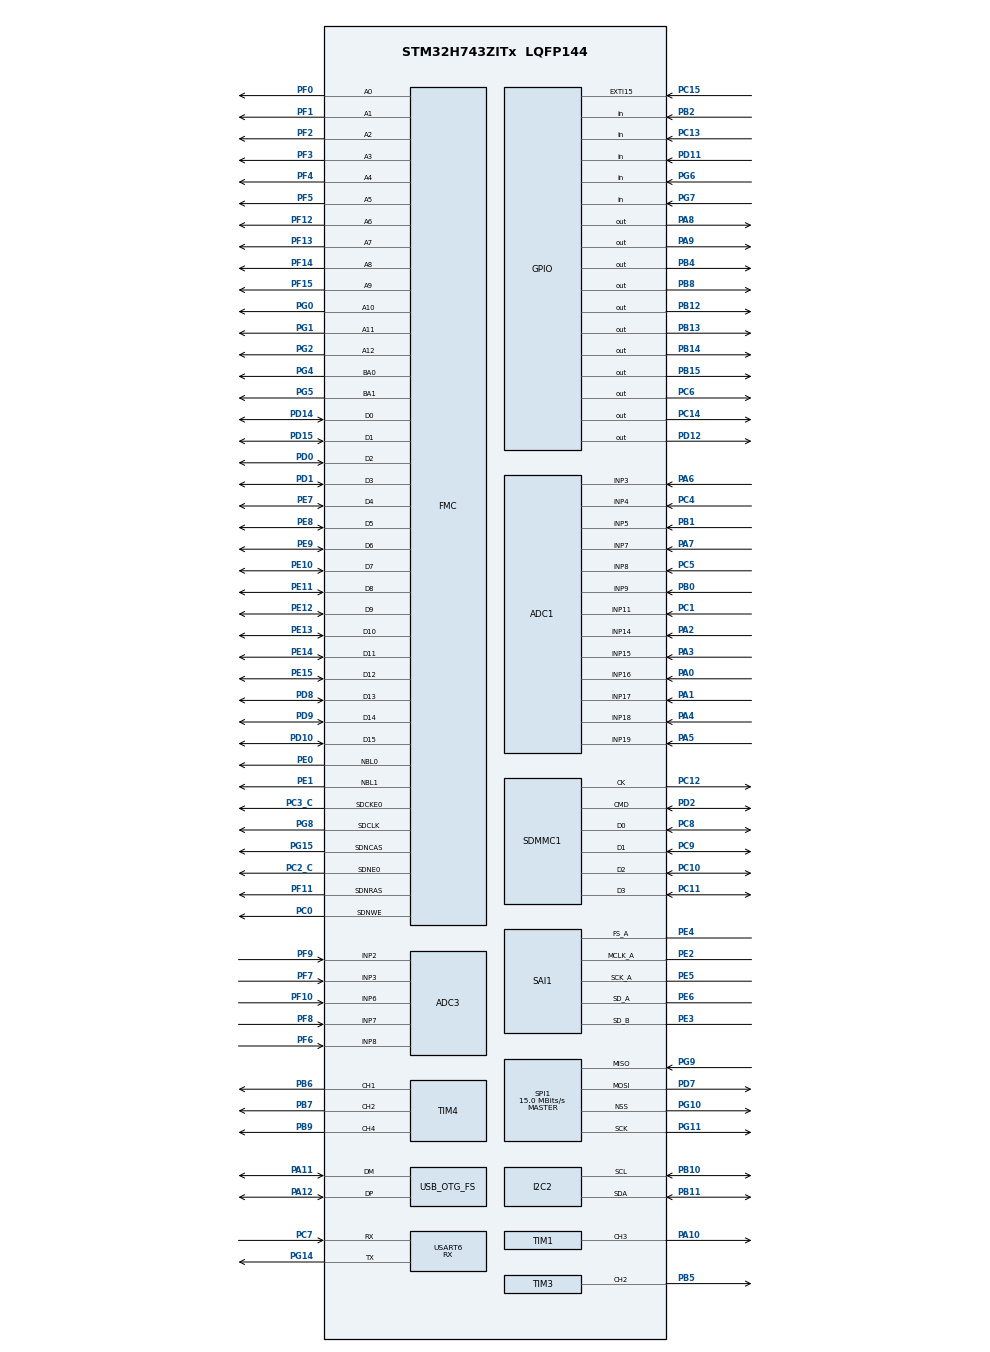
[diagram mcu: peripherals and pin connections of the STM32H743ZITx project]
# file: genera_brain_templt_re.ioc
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ADC1.Channel-0\#ChannelRegularConversion=ADC_CHANNEL_7
ADC1.Channel-1\#ChannelRegularConversion=ADC_CHANNEL_19
ADC1.Channel-2\#ChannelRegularConversion=ADC_CHANNEL_15
ADC1.Channel-3\#ChannelRegularConversion=ADC_CHANNEL_3
ADC1.Channel-4\#ChannelRegularConversion=ADC_CHANNEL_18
ADC1.Channel-5\#ChannelRegularConversion=ADC_CHANNEL_14
ADC1.Channel-6\#ChannelRegularConversion=ADC_CHANNEL_4
ADC1.Channel-7\#ChannelRegularConversion=ADC_CHANNEL_8
ADC1.Channel-8\#ChannelRegularConversion=ADC_CHANNEL_9
ADC1.Channel-9\#ChannelRegularConversion=ADC_CHANNEL_5
ADC1.ClockPrescaler=ADC_CLOCK_ASYNC_DIV16
ADC1.ContinuousConvMode=ENABLE
ADC1.ConversionDataManagement=ADC_CONVERSIONDATA_DMA_CIRCULAR
ADC1.EOCSelection=ADC_EOC_SEQ_CONV
ADC1.NbrOfConversion=10
ADC1.NbrOfConversionFlag=1
ADC1.OffsetNumber-0\#ChannelRegularConversion=ADC_OFFSET_NONE
ADC1.OffsetNumber-1\#ChannelRegularConversion=ADC_OFFSET_NONE
ADC1.OffsetNumber-2\#ChannelRegularConversion=ADC_OFFSET_NONE
ADC1.OffsetNumber-3\#ChannelRegularConversion=ADC_OFFSET_NONE
ADC1.OffsetNumber-4\#ChannelRegularConversion=ADC_OFFSET_NONE
ADC1.OffsetNumber-5\#ChannelRegularConversion=ADC_OFFSET_NONE
ADC1.OffsetNumber-6\#ChannelRegularConversion=ADC_OFFSET_NONE
ADC1.OffsetNumber-7\#ChannelRegularConversion=ADC_OFFSET_NONE
ADC1.OffsetNumber-8\#ChannelRegularConversion=ADC_OFFSET_NONE
ADC1.OffsetNumber-9\#ChannelRegularConversion=ADC_OFFSET_NONE
ADC1.OffsetSignedSaturation-6\#ChannelRegularConversion=DISABLE
ADC1.OffsetSignedSaturation-7\#ChannelRegularConversion=DISABLE
ADC1.OffsetSignedSaturation-8\#ChannelRegularConversion=DISABLE
ADC1.OffsetSignedSaturation-9\#ChannelRegularConversion=DISABLE
ADC1.Rank-0\#ChannelRegularConversion=1
ADC1.Rank-1\#ChannelRegularConversion=2
ADC1.Rank-2\#ChannelRegularConversion=3
ADC1.Rank-3\#ChannelRegularConversion=4
ADC1.Rank-4\#ChannelRegularConversion=5
ADC1.Rank-5\#ChannelRegularConversion=6
ADC1.Rank-6\#ChannelRegularConversion=7
ADC1.Rank-7\#ChannelRegularConversion=8
ADC1.Rank-8\#ChannelRegularConversion=9
ADC1.Rank-9\#ChannelRegularConversion=10
ADC1.SamplingTime-0\#ChannelRegularConversion=ADC_SAMPLETIME_387CYCLES_5
ADC1.SamplingTime-1\#ChannelRegularConversion=ADC_SAMPLETIME_387CYCLES_5
ADC1.SamplingTime-2\#ChannelRegularConversion=ADC_SAMPLETIME_387CYCLES_5
ADC1.SamplingTime-3\#ChannelRegularConversion=ADC_SAMPLETIME_387CYCLES_5
ADC1.SamplingTime-4\#ChannelRegularConversion=ADC_SAMPLETIME_387CYCLES_5
ADC1.SamplingTime-5\#ChannelRegularConversion=ADC_SAMPLETIME_387CYCLES_5
ADC1.SamplingTime-6\#ChannelRegularConversion=ADC_SAMPLETIME_1CYCLE_5
ADC1.SamplingTime-7\#ChannelRegularConversion=ADC_SAMPLETIME_1CYCLE_5
ADC1.SamplingTime-8\#ChannelRegularConversion=ADC_SAMPLETIME_1CYCLE_5
ADC1.SamplingTime-9\#ChannelRegularConversion=ADC_SAMPLETIME_1CYCLE_5
ADC1.master=1
ADC3.Channel-1\#ChannelRegularConversion=ADC_CHANNEL_2
ADC3.Channel-2\#ChannelRegularConversion=ADC_CHANNEL_2
ADC3.Channel-3\#ChannelRegularConversion=ADC_CHANNEL_2
ADC3.Channel-4\#ChannelRegularConversion=ADC_CHANNEL_2
ADC3.Channel-5\#ChannelRegularConversion=ADC_CHANNEL_2
ADC3.ClockPrescaler=ADC_CLOCK_ASYNC_DIV16
ADC3.ContinuousConvMode=ENABLE
ADC3.NbrOfConversion=5
ADC3.NbrOfConversionFlag=1
ADC3.OffsetNumber-1\#ChannelRegularConversion=ADC_OFFSET_NONE
ADC3.OffsetNumber-2\#ChannelRegularConversion=ADC_OFFSET_NONE
ADC3.OffsetNumber-3\#ChannelRegularConversion=ADC_OFFSET_NONE
ADC3.OffsetNumber-4\#ChannelRegularConversion=ADC_OFFSET_NONE
ADC3.OffsetNumber-5\#ChannelRegularConversion=ADC_OFFSET_NONE
ADC3.Rank-1\#ChannelRegularConversion=1
ADC3.Rank-2\#ChannelRegularConversion=2
ADC3.Rank-3\#ChannelRegularConversion=3
ADC3.Rank-4\#ChannelRegularConversion=4
ADC3.Rank-5\#ChannelRegularConversion=5
ADC3.SamplingTime-1\#ChannelRegularConversion=ADC_SAMPLETIME_1CYCLE_5
ADC3.SamplingTime-2\#ChannelRegularConversion=ADC_SAMPLETIME_1CYCLE_5
ADC3.SamplingTime-3\#ChannelRegularConversion=ADC_SAMPLETIME_1CYCLE_5
ADC3.SamplingTime-4\#ChannelRegularConversion=ADC_SAMPLETIME_1CYCLE_5
ADC3.SamplingTime-5\#ChannelRegularConversion=ADC_SAMPLETIME_1CYCLE_5
CORTEX_M7.CPU_DCache=Enabled
CORTEX_M7.CPU_ICache=Enabled
Dma.ADC1.0.Direction=DMA_PERIPH_TO_MEMORY
Dma.ADC1.0.EventEnable=DISABLE
Dma.ADC1.0.FIFOMode=DMA_FIFOMODE_ENABLE
Dma.ADC1.0.FIFOThreshold=DMA_FIFO_THRESHOLD_1QUARTERFULL
Dma.ADC1.0.Instance=DMA1_Stream0
Dma.ADC1.0.MemBurst=DMA_MBURST_SINGLE
Dma.ADC1.0.MemDataAlignment=DMA_MDATAALIGN_HALFWORD
Dma.ADC1.0.MemInc=DMA_MINC_ENABLE
Dma.ADC1.0.Mode=DMA_CIRCULAR
Dma.ADC1.0.PeriphBurst=DMA_PBURST_SINGLE
Dma.ADC1.0.PeriphDataAlignment=DMA_PDATAALIGN_HALFWORD
Dma.ADC1.0.PeriphInc=DMA_PINC_DISABLE
Dma.ADC1.0.Polarity=HAL_DMAMUX_REQ_GEN_RISING
Dma.ADC1.0.Priority=DMA_PRIORITY_HIGH
Dma.ADC1.0.RequestNumber=1
Dma.ADC1.0.SignalID=NONE
Dma.ADC1.0.SyncEnable=DISABLE
Dma.ADC1.0.SyncPolarity=HAL_DMAMUX_SYNC_NO_EVENT
Dma.ADC1.0.SyncRequestNumber=1
Dma.ADC1.0.SyncSignalID=NONE
Dma.Request0=ADC1
Dma.Request1=SAI1_A
Dma.Request2=SAI1_B
Dma.SAI1_A.1.Direction=DMA_MEMORY_TO_PERIPH
Dma.SAI1_A.1.EventEnable=DISABLE
Dma.SAI1_A.1.FIFOMode=DMA_FIFOMODE_ENABLE
Dma.SAI1_A.1.FIFOThreshold=DMA_FIFO_THRESHOLD_1QUARTERFULL
Dma.SAI1_A.1.Instance=DMA1_Stream1
Dma.SAI1_A.1.MemBurst=DMA_MBURST_SINGLE
Dma.SAI1_A.1.MemDataAlignment=DMA_MDATAALIGN_WORD
Dma.SAI1_A.1.MemInc=DMA_MINC_ENABLE
Dma.SAI1_A.1.Mode=DMA_CIRCULAR
Dma.SAI1_A.1.PeriphBurst=DMA_PBURST_SINGLE
Dma.SAI1_A.1.PeriphDataAlignment=DMA_PDATAALIGN_WORD
Dma.SAI1_A.1.PeriphInc=DMA_PINC_DISABLE
Dma.SAI1_A.1.Polarity=HAL_DMAMUX_REQ_GEN_RISING
Dma.SAI1_A.1.Priority=DMA_PRIORITY_VERY_HIGH
Dma.SAI1_A.1.RequestNumber=1
Dma.SAI1_A.1.SignalID=NONE
Dma.SAI1_A.1.SyncEnable=DISABLE
Dma.SAI1_A.1.SyncPolarity=HAL_DMAMUX_SYNC_NO_EVENT
Dma.SAI1_A.1.SyncRequestNumber=1
Dma.SAI1_A.1.SyncSignalID=NONE
Dma.SAI1_B.2.Direction=DMA_PERIPH_TO_MEMORY
Dma.SAI1_B.2.EventEnable=DISABLE
Dma.SAI1_B.2.FIFOMode=DMA_FIFOMODE_ENABLE
Dma.SAI1_B.2.FIFOThreshold=DMA_FIFO_THRESHOLD_1QUARTERFULL
Dma.SAI1_B.2.Instance=DMA1_Stream2
Dma.SAI1_B.2.MemBurst=DMA_MBURST_SINGLE
Dma.SAI1_B.2.MemDataAlignment=DMA_MDATAALIGN_WORD
Dma.SAI1_B.2.MemInc=DMA_MINC_ENABLE
Dma.SAI1_B.2.Mode=DMA_CIRCULAR
Dma.SAI1_B.2.PeriphBurst=DMA_PBURST_SINGLE
Dma.SAI1_B.2.PeriphDataAlignment=DMA_PDATAALIGN_WORD
Dma.SAI1_B.2.PeriphInc=DMA_PINC_DISABLE
Dma.SAI1_B.2.Polarity=HAL_DMAMUX_REQ_GEN_RISING
Dma.SAI1_B.2.Priority=DMA_PRIORITY_VERY_HIGH
Dma.SAI1_B.2.RequestNumber=1
Dma.SAI1_B.2.SignalID=NONE
Dma.SAI1_B.2.SyncEnable=DISABLE
Dma.SAI1_B.2.SyncPolarity=HAL_DMAMUX_SYNC_NO_EVENT
Dma.SAI1_B.2.SyncRequestNumber=1
Dma.SAI1_B.2.SyncSignalID=NONE
FATFS.BSP.number=1
FATFS0.BSP.STBoard=false
FATFS0.BSP.api=Unknown
FATFS0.BSP.instance=PC13
FATFS0.BSP.ip=GPIO
FATFS0.BSP.mode=Input
FATFS0.BSP.name=Detect_SDIO
FATFS0.BSP.solution=PC13
FMC.BankMapConfig=FMC_SWAPBMAP_SDRAM_SRAM
FMC.CASLatency1=FMC_SDRAM_CAS_LATENCY_2
FMC.ColumnBitsNumber1=FMC_SDRAM_COLUMN_BITS_NUM_9
FMC.ExitSelfRefreshDelay1=6
FMC.LoadToActiveDelay1=2
FMC.RCDDelay1=2
FMC.RPDelay1=2
FMC.RPDelay2=2
FMC.ReadBurst1=FMC_SDRAM_RBURST_ENABLE
FMC.ReadBurst2=FMC_SDRAM_RBURST_ENABLE
FMC.RowCycleDelay1=6
FMC.RowCycleDelay2=6
FMC.SDClockPeriod1=FMC_SDRAM_CLOCK_PERIOD_3
FMC.SDClockPeriod2=FMC_SDRAM_CLOCK_PERIOD_3
FMC.SelfRefreshTime1=4
FMC.WriteRecoveryTime1=2
I2C2.Analog_Filter=I2C_ANALOGFILTER_ENABLE
I2C2.I2C_Coeff_DF=0
I2C2.I2C_Fall_Time=5
I2C2.I2C_Rise_Time=10
I2C2.NoStretchMode=I2C_NOSTRETCH_DISABLE
I2C2.Speed=50
I2C2.Timing=0x505097F4
Mcu.Family=STM32H7
Mcu.Name=STM32H743ZITx
Mcu.Package=LQFP144
NVIC.ADC_IRQn=true\:0\:0\:false\:false\:true\:true\:true\:true
NVIC.DMA1_Stream0_IRQn=true\:0\:0\:false\:false\:true\:false\:true\:true
NVIC.DMA1_Stream1_IRQn=true\:0\:0\:false\:false\:true\:false\:true\:true
NVIC.DMA1_Stream2_IRQn=true\:0\:0\:false\:false\:true\:false\:true\:true
NVIC.OTG_FS_EP1_IN_IRQn=true\:6\:0\:true\:false\:true\:true\:true\:true
NVIC.OTG_FS_EP1_OUT_IRQn=true\:6\:0\:true\:false\:true\:true\:true\:true
NVIC.OTG_FS_IRQn=true\:0\:0\:false\:false\:true\:false\:true\:true
NVIC.PriorityGroup=NVIC_PRIORITYGROUP_4
PA0.Mode=IN16-Single-Ended
PA0.Signal=ADC1_INP16
PA1.Mode=IN17-Single-Ended
PA1.Signal=ADC1_INP17
PA10.Signal=S_TIM1_CH3
PA11.GPIO_Speed=GPIO_SPEED_FREQ_VERY_HIGH
PA11.Mode=Host_Only
PA11.Signal=USB_OTG_FS_DM
PA12.GPIO_Speed=GPIO_SPEED_FREQ_VERY_HIGH
PA12.Mode=Host_Only
PA12.Signal=USB_OTG_FS_DP
PA13\ (JTMS/SWDIO).Mode=Trace_Asynchronous_SW
PA13\ (JTMS/SWDIO).Signal=DEBUG_JTMS-SWDIO
PA14\ (JTCK/SWCLK).Mode=Trace_Asynchronous_SW
PA14\ (JTCK/SWCLK).Signal=DEBUG_JTCK-SWCLK
PA2.Signal=ADCx_INP14
PA3.Signal=ADCx_INP15
PA4.Signal=ADCx_INP18
PA5.Signal=ADCx_INP19
PA6.Signal=ADCx_INP3
PA7.Signal=ADCx_INP7
PA8.Signal=GPIO_Output
PA9.Signal=GPIO_Output
PB0.Signal=ADCx_INP9
PB1.Signal=ADCx_INP5
PB10.GPIO_Pu=GPIO_PULLUP
PB10.GPIO_PuPd=GPIO_NOPULL
PB10.GPIO_Speed=GPIO_SPEED_FREQ_LOW
PB10.Mode=I2C
PB10.Signal=I2C2_SCL
PB11.GPIO_Pu=GPIO_PULLUP
PB11.GPIO_PuPd=GPIO_NOPULL
PB11.GPIO_Speed=GPIO_SPEED_FREQ_LOW
PB11.Mode=I2C
PB11.Signal=I2C2_SDA
PB12.Signal=GPIO_Output
PB13.Signal=GPIO_Output
PB14.Signal=GPIO_Output
PB15.Signal=GPIO_Output
PB2.Signal=GPIO_Input
PB3\ (JTDO/TRACESWO).Mode=Trace_Asynchronous_SW
PB3\ (JTDO/TRACESWO).Signal=DEBUG_JTDO-SWO
PB4\ (NJTRST).Signal=GPIO_Output
PB5.Signal=S_TIM3_CH2
PB6.Signal=S_TIM4_CH1
PB7.Signal=S_TIM4_CH2
PB8.Signal=GPIO_Output
PB9.Signal=S_TIM4_CH4
PC0.Signal=FMC_SDNWE
PC1.Signal=ADCx_INP11
PC10.GPIO_PuPd=GPIO_PULLUP
PC10.Mode=SD_4_bits_Wide_bus
PC10.Signal=SDMMC1_D2
PC11.GPIO_PuPd=GPIO_PULLUP
PC11.Mode=SD_4_bits_Wide_bus
PC11.Signal=SDMMC1_D3
PC12.Mode=SD_4_bits_Wide_bus
PC12.Signal=SDMMC1_CK
PC13.Signal=GPIO_Input
PC14-OSC32_IN\ (OSC32_IN).Signal=GPIO_Output
PC15-OSC32_OUT\ (OSC32_OUT).Signal=GPXTI15
PC2_C.Mode=SdramChipSelect1_1
PC2_C.Signal=FMC_SDNE0
PC3_C.Mode=SdramChipSelect1_1
PC3_C.Signal=FMC_SDCKE0
PC4.Signal=ADCx_INP4
PC5.Signal=ADCx_INP8
PC6.Signal=GPIO_Output
PC7.Mode=Asynchronous
PC7.Signal=USART6_RX
PC8.GPIO_PuPd=GPIO_PULLUP
PC8.Mode=SD_4_bits_Wide_bus
PC8.Signal=SDMMC1_D0
PC9.GPIO_PuPd=GPIO_PULLUP
PC9.Mode=SD_4_bits_Wide_bus
PC9.Signal=SDMMC1_D1
PD0.Signal=FMC_D2_DA2
PD1.Signal=FMC_D3_DA3
PD10.Signal=FMC_D15_DA15
PD11.GPIO_PuPd=GPIO_PULLUP
PD11.Signal=GPIO_Input
PD12.Signal=GPIO_Output
PD14.Signal=FMC_D0_DA0
PD15.Signal=FMC_D1_DA1
PD2.GPIO_PuPd=GPIO_PULLUP
PD2.Mode=SD_4_bits_Wide_bus
PD2.Signal=SDMMC1_CMD
PD7.Mode=Full_Duplex_Master
PD7.Signal=SPI1_MOSI
PD8.Signal=FMC_D13_DA13
PD9.Signal=FMC_D14_DA14
PE0.Signal=FMC_NBL0
PE1.Signal=FMC_NBL1
PE10.Signal=FMC_D7_DA7
PE11.Signal=FMC_D8_DA8
PE12.Signal=FMC_D9_DA9
PE13.Signal=FMC_D10_DA10
PE14.Signal=FMC_D11_DA11
PE15.Signal=FMC_D12_DA12
PE2.GPIO_Speed=GPIO_SPEED_FREQ_VERY_HIGH
PE2.Mode=SAI_A_MasterWithClock
PE2.Signal=SAI1_MCLK_A
PE3.GPIO_Speed=GPIO_SPEED_FREQ_HIGH
PE3.Mode=SAI_B_SyncSlave
PE3.Signal=SAI1_SD_B
PE4.GPIO_Speed=GPIO_SPEED_FREQ_HIGH
PE4.Mode=SAI_A_MasterWithClock
PE4.Signal=SAI1_FS_A
PE5.GPIO_Speed=GPIO_SPEED_FREQ_VERY_HIGH
PE5.Mode=SAI_A_MasterWithClock
PE5.Signal=SAI1_SCK_A
PE6.GPIO_Speed=GPIO_SPEED_FREQ_HIGH
PE6.Mode=SAI_A_MasterWithClock
PE6.Signal=SAI1_SD_A
PE7.Signal=FMC_D4_DA4
PE8.Signal=FMC_D5_DA5
PE9.Signal=FMC_D6_DA6
PF0.Signal=FMC_A0
PF1.Signal=FMC_A1
PF10.Mode=IN6-Single-Ended
PF10.Signal=ADC3_INP6
PF11.Signal=FMC_SDNRAS
PF12.Signal=FMC_A6
PF13.Signal=FMC_A7
PF14.Signal=FMC_A8
PF15.Signal=FMC_A9
PF2.Signal=FMC_A2
PF3.Signal=FMC_A3
PF4.Signal=FMC_A4
PF5.Signal=FMC_A5
PF6.Mode=IN8-Single-Ended
PF6.Signal=ADC3_INP8
PF7.Mode=IN3-Single-Ended
PF7.Signal=ADC3_INP3
PF8.Mode=IN7-Single-Ended
PF8.Signal=ADC3_INP7
PF9.Mode=IN2-Single-Ended
PF9.Signal=ADC3_INP2
PG0.Signal=FMC_A10
PG1.Signal=FMC_A11
PG10.Mode=NSS_Signal_Hard_Output
PG10.Signal=SPI1_NSS
PG11.Mode=Full_Duplex_Master
PG11.Signal=SPI1_SCK
PG14.Mode=Asynchronous
PG14.Signal=USART6_TX
PG15.Signal=FMC_SDNCAS
PG2.Signal=FMC_A12
PG4.Signal=FMC_A14_BA0
PG5.Signal=FMC_A15_BA1
PG6.GPIO_PuPd=GPIO_PULLUP
PG6.Signal=GPIO_Input
PG7.GPIO_PuPd=GPIO_PULLUP
PG7.Signal=GPIO_Input
PG8.Signal=FMC_SDCLK
PG9.Mode=Full_Duplex_Master
PG9.Signal=SPI1_MISO
PH0-OSC_IN\ (PH0).Mode=HSE-External-Oscillator
PH0-OSC_IN\ (PH0).Signal=RCC_OSC_IN
PH1-OSC_OUT\ (PH1).Mode=HSE-External-Oscillator
PH1-OSC_OUT\ (PH1).Signal=RCC_OSC_OUT
ProjectManager.HeapSize=0x200
ProjectManager.StackSize=0x400
ProjectManager.TargetToolchain=STM32CubeIDE
RCC.ADCFreq_Value=49142857.14285714
RCC.APB1Freq_Value=120000000
RCC.APB2Freq_Value=120000000
RCC.APB3Freq_Value=120000000
RCC.APB4Freq_Value=120000000
RCC.CortexFreq_Value=480000000
RCC.D1PPRE=RCC_APB3_DIV2
RCC.D2PPRE1=RCC_APB1_DIV2
RCC.D2PPRE2=RCC_APB2_DIV2
RCC.D3PPRE=RCC_APB4_DIV2
RCC.DIVM1=5
RCC.DIVM2=25
RCC.DIVN1=192
RCC.DIVN2=344
RCC.DIVP2=7
RCC.HCLKFreq_Value=240000000
RCC.HPRE=RCC_HCLK_DIV2
RCC.PLL2FRACN=0
RCC.PLL2_VCI_Range-AdvancedSettings=RCC_PLL2VCIRANGE_1
RCC.PLL3FRACN=0
RCC.PLL3_VCI_Range-AdvancedSettings=RCC_PLL3VCIRANGE_0
RCC.PLLFRACN=0
RCC.PLLSourceVirtual=RCC_PLLSOURCE_HSE
RCC.SAI1CLockSelection=RCC_SAI1CLKSOURCE_PLL2
RCC.SDMMC1CLockSelection=RCC_SDMMCCLKSOURCE_PLL2
RCC.SYSCLKFreq_VALUE=480000000
RCC.SYSCLKSource=RCC_SYSCLKSOURCE_PLLCLK
RCC.USBCLockSelection=RCC_USBCLKSOURCE_HSI48
RCC.USBFreq_Value=48000000
SAI1.AudioFrequency-SAI_A_MasterWithClock=SAI_AUDIO_FREQUENCY_48K
SAI1.BasicDataSize-SAI_A_MasterWithClock=SAI_PROTOCOL_DATASIZE_24BIT
SAI1.BasicDataSize-SAI_B_SyncSlave=SAI_PROTOCOL_DATASIZE_24BIT
SAI1.ErrorAudioFreq-SAI_A_MasterWithClock=-0.01 %
SAI1.FIFOThreshold-SAI_A_MasterWithClock=SAI_FIFOTHRESHOLD_1QF
SAI1.FIFOThreshold-SAI_B_SyncSlave=SAI_FIFOTHRESHOLD_1QF
SAI1.InitProtocol-SAI_A_MasterWithClock=Enable
SAI1.InitProtocol-SAI_B_SyncSlave=Enable
SAI1.Instance-SAI_A_MasterWithClock=SAI$Index_Block_A
SAI1.Instance-SAI_B_SyncSlave=SAI$Index_Block_B
SAI1.MClockEnable-SAI_A_MasterWithClock=SAI_MASTERCLOCK_ENABLE
SAI1.RealAudioFreq-SAI_A_MasterWithClock=47.991 KHz
SAI1.VirtualMode-SAI_A_MasterWithClock=VM_MASTER
SAI1.VirtualMode-SAI_B_SyncSlave=VM_SLAVE
SAI1.VirtualProtocol-SAI_A_BASIC=VM_BASIC_PROTOCOL
SAI1.VirtualProtocol-SAI_B_BASIC=VM_BASIC_PROTOCOL
SH.ADCx_INP11.0=ADC1_INP11,IN11-Single-Ended
SH.ADCx_INP14.0=ADC1_INP14,IN14-Single-Ended
SH.ADCx_INP15.0=ADC1_INP15,IN15-Single-Ended
SH.ADCx_INP18.0=ADC1_INP18,IN18-Single-Ended
SH.ADCx_INP19.0=ADC1_INP19,IN19-Single-Ended
SH.ADCx_INP3.0=ADC1_INP3,IN3-Single-Ended
SH.ADCx_INP4.0=ADC1_INP4,IN4-Single-Ended
SH.ADCx_INP5.0=ADC1_INP5,IN5-Single-Ended
SH.ADCx_INP7.0=ADC1_INP7,IN7-Single-Ended
SH.ADCx_INP8.0=ADC1_INP8,IN8-Single-Ended
SH.ADCx_INP9.0=ADC1_INP9,IN9-Single-Ended
SH.FMC_A0.0=FMC_A0,13b-sda1
SH.FMC_A1.0=FMC_A1,13b-sda1
SH.FMC_A10.0=FMC_A10,13b-sda1
SH.FMC_A11.0=FMC_A11,13b-sda1
SH.FMC_A12.0=FMC_A12,13b-sda1
SH.FMC_A14_BA0.0=FMC_BA0,FourSdramBanks1
SH.FMC_A15_BA1.0=FMC_BA1,FourSdramBanks1
SH.FMC_A2.0=FMC_A2,13b-sda1
SH.FMC_A3.0=FMC_A3,13b-sda1
SH.FMC_A4.0=FMC_A4,13b-sda1
SH.FMC_A5.0=FMC_A5,13b-sda1
SH.FMC_A6.0=FMC_A6,13b-sda1
SH.FMC_A7.0=FMC_A7,13b-sda1
SH.FMC_A8.0=FMC_A8,13b-sda1
SH.FMC_A9.0=FMC_A9,13b-sda1
SH.FMC_D0_DA0.0=FMC_D0,sd-16b-d1
SH.FMC_D10_DA10.0=FMC_D10,sd-16b-d1
SH.FMC_D11_DA11.0=FMC_D11,sd-16b-d1
SH.FMC_D12_DA12.0=FMC_D12,sd-16b-d1
SH.FMC_D13_DA13.0=FMC_D13,sd-16b-d1
SH.FMC_D14_DA14.0=FMC_D14,sd-16b-d1
SH.FMC_D15_DA15.0=FMC_D15,sd-16b-d1
SH.FMC_D1_DA1.0=FMC_D1,sd-16b-d1
SH.FMC_D2_DA2.0=FMC_D2,sd-16b-d1
SH.FMC_D3_DA3.0=FMC_D3,sd-16b-d1
SH.FMC_D4_DA4.0=FMC_D4,sd-16b-d1
SH.FMC_D5_DA5.0=FMC_D5,sd-16b-d1
SH.FMC_D6_DA6.0=FMC_D6,sd-16b-d1
SH.FMC_D7_DA7.0=FMC_D7,sd-16b-d1
SH.FMC_D8_DA8.0=FMC_D8,sd-16b-d1
SH.FMC_D9_DA9.0=FMC_D9,sd-16b-d1
SH.FMC_NBL0.0=FMC_NBL0,Sd2ByteEnable1
SH.FMC_NBL1.0=FMC_NBL1,Sd2ByteEnable1
SH.FMC_SDCLK.0=FMC_SDCLK,13b-sda1
SH.FMC_SDNCAS.0=FMC_SDNCAS,13b-sda1
SH.FMC_SDNRAS.0=FMC_SDNRAS,13b-sda1
SH.FMC_SDNWE.0=FMC_SDNWE,13b-sda1
SH.S_TIM1_CH3.0=TIM1_CH3,PWM Generation3 CH3
SH.S_TIM3_CH2.0=TIM3_CH2,PWM Generation2 CH2
SH.S_TIM4_CH1.0=TIM4_CH1,PWM Generation1 CH1
SH.S_TIM4_CH2.0=TIM4_CH2,PWM Generation2 CH2
SH.S_TIM4_CH4.0=TIM4_CH4,PWM Generation4 CH4
SPI1.BaudRatePrescaler=SPI_BAUDRATEPRESCALER_32
SPI1.CalculateBaudRate=15.0 MBits/s
SPI1.DataSize=SPI_DATASIZE_8BIT
SPI1.Direction=SPI_DIRECTION_2LINES
SPI1.Mode=SPI_MODE_MASTER
SPI1.VirtualNSS=VM_NSSHARD
SPI1.VirtualType=VM_MASTER
TIM1.Channel-PWM\ Generation3\ CH3=TIM_CHANNEL_3
TIM3.Channel-PWM\ Generation2\ CH2=TIM_CHANNEL_2
TIM4.Channel-PWM\ Generation1\ CH1=TIM_CHANNEL_1
TIM4.Channel-PWM\ Generation2\ CH2=TIM_CHANNEL_2
TIM4.Channel-PWM\ Generation4\ CH4=TIM_CHANNEL_4
USART6.Mode=MODE_RX
USART6.VirtualMode-Asynchronous=VM_ASYNC
USB_HOST.BSP.number=1
USB_HOST.USBH_HandleTypeDef-AUDIO_FS=hUsbHostFS
USB_HOST.VirtualModeFS=Audio
USB_HOST0.BSP.STBoard=false
USB_HOST0.BSP.api=Unknown
USB_HOST0.BSP.instance=PB8
USB_HOST0.BSP.ip=GPIO
USB_HOST0.BSP.mode=Output
USB_HOST0.BSP.name=Drive_VBUS_FS
USB_HOST0.BSP.solution=PB8
USB_OTG_FS.VirtualMode=Host_Only
USB_OTG_FS.dma_enable=ENABLE
USB_OTG_FS.phy_itface=HCD_PHY_EMBEDDED
VP_FATFS_VS_SDIO.Mode=SDIO
VP_RNG_VS_RNG.Mode=RNG_Activate
VP_SAI1_VP_$IpInstance_SAIA_SAI_BASIC.Mode=SAI_A_BASIC
VP_SAI1_VP_$IpInstance_SAIB_SAI_BASIC.Mode=SAI_B_BASIC
VP_TIM3_VS_ClockSourceINT.Mode=Internal
VP_TIM4_VS_ClockSourceINT.Mode=Internal
VP_TIM7_VS_ClockSourceINT.Mode=Enable_Timer
VP_USB_HOST_VS_USB_HOST_AUDIO_FS.Mode=AUDIO_FS
board=custom

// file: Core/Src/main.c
/* USER CODE BEGIN Header */
/**
  ******************************************************************************
  * @file           : main.c
  * @brief          : Main program body
  ******************************************************************************
  * @attention
  *
  * <h2><center>&copy; Copyright (c) 2019 STMicroelectronics.
  * All rights reserved.</center></h2>
  *
  * This software component is licensed by ST under Ultimate Liberty license
  * SLA0044, the "License"; You may not use this file except in compliance with
  * the License. You may obtain a copy of the License at:
  *                             www.st.com/SLA0044
  *
  ******************************************************************************
  */
/* USER CODE END Header */
#include "main.h"
#include "adc.h"
#include "dma.h"
#include "fatfs.h"
#include "i2c.h"
#include "rng.h"
#include "sai.h"
#include "sdmmc.h"
#include "spi.h"
#include "tim.h"
#include "usart.h"
#include "usb_host.h"
#include "gpio.h"
#include "fmc.h"

/* USER CODE BEGIN Includes */
#include "ui.h"
#include "leaf.h"
#include "audiostream.h"
/* USER CODE END Includes */

void SystemClock_Config(void);
void PeriphCommonClock_Config(void);
void MX_USB_HOST_Process(void);

/* USER CODE BEGIN PFP */
void MPU_Conf(void);
void SDRAM_Initialization_sequence(void);
/* USER CODE END PFP */

int main(void)
{
  /* USER CODE BEGIN 1 */
  MPU_Conf();
  /* USER CODE END 1 */
/* Enable the CPU Cache */

  /* Enable I-Cache---------------------------------------------------------*/
  SCB_EnableICache();

  /* Enable D-Cache---------------------------------------------------------*/
  SCB_EnableDCache();

  /* MCU Configuration--------------------------------------------------------*/

  /* Reset of all peripherals, Initializes the Flash interface and the Systick. */
  HAL_Init();

  /* Configure the system clock */
  SystemClock_Config();

/* Configure the peripherals common clocks */
  PeriphCommonClock_Config();

  /* Initialize all configured peripherals */
  MX_GPIO_Init();
  MX_DMA_Init();
  MX_FMC_Init();
  MX_ADC1_Init();
  MX_ADC3_Init();
  MX_I2C2_Init();
  MX_SDMMC1_SD_Init();
  MX_SPI1_Init();
  MX_FATFS_Init();
  MX_SAI1_Init();
  MX_TIM3_Init();
  MX_TIM4_Init();
  MX_TIM7_Init();
  MX_TIM1_Init();
  MX_USART6_UART_Init();
  MX_RNG_Init();
  MX_USB_HOST_Init();
  /* USER CODE BEGIN 2 */
	//HAL_Delay(200);
  //pull reset pin on audio codec low to make sure it's stable
  HAL_GPIO_WritePin(GPIOC, GPIO_PIN_14, GPIO_PIN_RESET);

  uint32_t tempFPURegisterVal = __get_FPSCR();
  tempFPURegisterVal |= (1<<24); // set the FTZ (flush-to-zero) bit in the FPU control register
  __set_FPSCR(tempFPURegisterVal);

  if (HAL_ADC_Start_DMA(&hadc1,(uint32_t*)&ADC_values, NUM_ADC_CHANNELS) != HAL_OK)
	{
	  Error_Handler();
	}
//  HAL_GPIO_WritePin(GPIOC, GPIO_PIN_6, GPIO_PIN_SET);
  HAL_Delay(10);

  SDRAM_Initialization_sequence();
  HAL_Delay(100);

  audioInit(&hi2c2, &hsai_BlockA1, &hsai_BlockB1);
  //HAL_GPIO_WritePin(GPIOB, GPIO_PIN_15, GPIO_PIN_SET);
  //HAL_GPIO_WritePin(GPIOD, GPIO_PIN_12, GPIO_PIN_SET);
  /* USER CODE END 2 */

  /* Infinite loop */
  while (1)
  {
    MX_USB_HOST_Process();

  }
}

void SystemClock_Config(void)
{
  RCC_OscInitTypeDef RCC_OscInitStruct = {0};
  RCC_ClkInitTypeDef RCC_ClkInitStruct = {0};

  /** Supply configuration update enable
  */
  HAL_PWREx_ConfigSupply(PWR_LDO_SUPPLY);

  /** Configure the main internal regulator output voltage
  */
  __HAL_PWR_VOLTAGESCALING_CONFIG(PWR_REGULATOR_VOLTAGE_SCALE1);

  while(!__HAL_PWR_GET_FLAG(PWR_FLAG_VOSRDY)) {}

  __HAL_RCC_SYSCFG_CLK_ENABLE();
  __HAL_PWR_VOLTAGESCALING_CONFIG(PWR_REGULATOR_VOLTAGE_SCALE0);

  while(!__HAL_PWR_GET_FLAG(PWR_FLAG_VOSRDY)) {}

  /** Initializes the RCC Oscillators according to the specified parameters
  * in the RCC_OscInitTypeDef structure.
  */
  RCC_OscInitStruct.OscillatorType = RCC_OSCILLATORTYPE_HSI48|RCC_OSCILLATORTYPE_HSE;
  RCC_OscInitStruct.HSEState = RCC_HSE_ON;
  RCC_OscInitStruct.HSI48State = RCC_HSI48_ON;
  RCC_OscInitStruct.PLL.PLLState = RCC_PLL_ON;
  RCC_OscInitStruct.PLL.PLLSource = RCC_PLLSOURCE_HSE;
  RCC_OscInitStruct.PLL.PLLM = 5;
  RCC_OscInitStruct.PLL.PLLN = 192;
  RCC_OscInitStruct.PLL.PLLP = 2;
  RCC_OscInitStruct.PLL.PLLQ = 2;
  RCC_OscInitStruct.PLL.PLLR = 2;
  RCC_OscInitStruct.PLL.PLLRGE = RCC_PLL1VCIRANGE_2;
  RCC_OscInitStruct.PLL.PLLVCOSEL = RCC_PLL1VCOWIDE;
  RCC_OscInitStruct.PLL.PLLFRACN = 0;
  if (HAL_RCC_OscConfig(&RCC_OscInitStruct) != HAL_OK)
  {
    Error_Handler();
  }

  /** Initializes the CPU, AHB and APB buses clocks
  */
  RCC_ClkInitStruct.ClockType = RCC_CLOCKTYPE_HCLK|RCC_CLOCKTYPE_SYSCLK
                              |RCC_CLOCKTYPE_PCLK1|RCC_CLOCKTYPE_PCLK2
                              |RCC_CLOCKTYPE_D3PCLK1|RCC_CLOCKTYPE_D1PCLK1;
  RCC_ClkInitStruct.SYSCLKSource = RCC_SYSCLKSOURCE_PLLCLK;
  RCC_ClkInitStruct.SYSCLKDivider = RCC_SYSCLK_DIV1;
  RCC_ClkInitStruct.AHBCLKDivider = RCC_HCLK_DIV2;
  RCC_ClkInitStruct.APB3CLKDivider = RCC_APB3_DIV2;
  RCC_ClkInitStruct.APB1CLKDivider = RCC_APB1_DIV2;
  RCC_ClkInitStruct.APB2CLKDivider = RCC_APB2_DIV2;
  RCC_ClkInitStruct.APB4CLKDivider = RCC_APB4_DIV2;

  if (HAL_RCC_ClockConfig(&RCC_ClkInitStruct, FLASH_LATENCY_4) != HAL_OK)
  {
    Error_Handler();
  }
}

void PeriphCommonClock_Config(void)
{
  RCC_PeriphCLKInitTypeDef PeriphClkInitStruct = {0};

  /** Initializes the peripherals clock
  */
  PeriphClkInitStruct.PeriphClockSelection = RCC_PERIPHCLK_ADC|RCC_PERIPHCLK_SDMMC
                              |RCC_PERIPHCLK_SAI1;
  PeriphClkInitStruct.PLL2.PLL2M = 25;
  PeriphClkInitStruct.PLL2.PLL2N = 344;
  PeriphClkInitStruct.PLL2.PLL2P = 7;
  PeriphClkInitStruct.PLL2.PLL2Q = 2;
  PeriphClkInitStruct.PLL2.PLL2R = 2;
  PeriphClkInitStruct.PLL2.PLL2RGE = RCC_PLL2VCIRANGE_0;
  PeriphClkInitStruct.PLL2.PLL2VCOSEL = RCC_PLL2VCOWIDE;
  PeriphClkInitStruct.PLL2.PLL2FRACN = 0;
  PeriphClkInitStruct.SdmmcClockSelection = RCC_SDMMCCLKSOURCE_PLL2;
  PeriphClkInitStruct.Sai1ClockSelection = RCC_SAI1CLKSOURCE_PLL2;
  PeriphClkInitStruct.AdcClockSelection = RCC_ADCCLKSOURCE_PLL2;
  if (HAL_RCCEx_PeriphCLKConfig(&PeriphClkInitStruct) != HAL_OK)
  {
    Error_Handler();
  }
}

/* USER CODE BEGIN 4 */
void HAL_ADC_ConvCpltCallback(ADC_HandleTypeDef *hadc)
{
	;
}

#define SDRAM_TIMEOUT ((uint32_t)0xFFFF)

#define SDRAM_MODEREG_BURST_LENGTH_1             ((uint16_t)0x0000)
#define SDRAM_MODEREG_BURST_LENGTH_2             ((uint16_t)0x0001)
#define SDRAM_MODEREG_BURST_LENGTH_4             ((uint16_t)0x0002)
#define SDRAM_MODEREG_BURST_LENGTH_8             ((uint16_t)0x0003)
#define SDRAM_MODEREG_BURST_TYPE_SEQUENTIAL      ((uint16_t)0x0000)
#define SDRAM_MODEREG_BURST_TYPE_INTERLEAVED     ((uint16_t)0x0008)
#define SDRAM_MODEREG_CAS_LATENCY_2              ((uint16_t)0x0020)
#define SDRAM_MODEREG_CAS_LATENCY_3              ((uint16_t)0x0030)
#define SDRAM_MODEREG_OPERATING_MODE_STANDARD    ((uint16_t)0x0000)
#define SDRAM_MODEREG_WRITEBURST_MODE_PROGRAMMED ((uint16_t)0x0000)
#define SDRAM_MODEREG_WRITEBURST_MODE_SINGLE     ((uint16_t)0x0200)

//#define SDRAM_REFRESH_COUNT                   	 ((uint32_t)956)// 7.9us in cycles of 8.333333ns + 20 cycles as recommended by datasheet page 866/3289 for STM32H743
#define SDRAM_REFRESH_COUNT                   	 ((uint32_t)0x0569)// 7.9us in cycles of 8.333333ns + 20 cycles as recommended by datasheet page 866/3289 for STM32H743
void SDRAM_Initialization_sequence(void)
{
    __IO uint32_t tmpmrd = 0;
    FMC_SDRAM_CommandTypeDef Command;
    /* Step 1: Configure a clock configuration enable command */
    Command.CommandMode = FMC_SDRAM_CMD_CLK_ENABLE;
    Command.CommandTarget = FMC_SDRAM_CMD_TARGET_BANK1;
    Command.AutoRefreshNumber = 1;
    Command.ModeRegisterDefinition = 0;

    /* Send the command */
    HAL_SDRAM_SendCommand(&hsdram1, &Command, SDRAM_TIMEOUT);

    /* Step 2: Insert 100 us minimum delay */
    /* Inserted delay is equal to 1 ms due to systick time base unit (ms) */
    HAL_Delay(1);

    /* Step 3: Configure a PALL (precharge all) command */
    Command.CommandMode = FMC_SDRAM_CMD_PALL;
    Command.CommandTarget = FMC_SDRAM_CMD_TARGET_BANK1;
    Command.AutoRefreshNumber = 1;
    Command.ModeRegisterDefinition = 0;

    /* Send the command */
    HAL_SDRAM_SendCommand(&hsdram1, &Command, SDRAM_TIMEOUT);

    /* Step 5: Program the external memory mode register */
    tmpmrd = (uint32_t)SDRAM_MODEREG_BURST_LENGTH_4 | SDRAM_MODEREG_BURST_TYPE_SEQUENTIAL
        | SDRAM_MODEREG_CAS_LATENCY_2 | SDRAM_MODEREG_OPERATING_MODE_STANDARD
        | SDRAM_MODEREG_WRITEBURST_MODE_SINGLE;

    Command.CommandMode = FMC_SDRAM_CMD_LOAD_MODE;
    Command.CommandTarget = FMC_SDRAM_CMD_TARGET_BANK1;
    Command.AutoRefreshNumber = 1;
    Command.ModeRegisterDefinition = tmpmrd;

    /* Send the command */
    HAL_SDRAM_SendCommand(&hsdram1, &Command, SDRAM_TIMEOUT);

    /* Step 4: Configure the 1st Auto Refresh command */
    Command.CommandMode = FMC_SDRAM_CMD_AUTOREFRESH_MODE;
    Command.CommandTarget = FMC_SDRAM_CMD_TARGET_BANK1;
    Command.AutoRefreshNumber = 8;
    Command.ModeRegisterDefinition = 0;

    /* Send the command */
    HAL_SDRAM_SendCommand(&hsdram1, &Command, SDRAM_TIMEOUT);

    /* Step 2: Insert 100 us minimum delay */
    /* Inserted delay is equal to 1 ms due to systick time base unit (ms) */
    HAL_Delay(1);

    /* Step 5: Configure the 2nd Auto Refresh command */
    Command.CommandMode = FMC_SDRAM_CMD_AUTOREFRESH_MODE;
    Command.CommandTarget = FMC_SDRAM_CMD_TARGET_BANK1;
    Command.AutoRefreshNumber = 8;
    Command.ModeRegisterDefinition = 0;

    /* Send the command */
    HAL_SDRAM_SendCommand(&hsdram1, &Command, SDRAM_TIMEOUT);

    /* Step 6: Set the refresh rate counter */
    /* Set the device refresh rate */
    HAL_SDRAM_ProgramRefreshRate(&hsdram1, SDRAM_REFRESH_COUNT);
}

float randomNumber(void) {

	uint32_t rand;
	HAL_RNG_GenerateRandomNumber(&hrng, &rand);
	float num = (float)rand * INV_TWO_TO_32;
	return num;
}

void MPU_Conf(void)
{
	//code from Keshikan https://github.com/keshikan/STM32H7_DMA_sample
  //Thanks, Keshikan! This solves the issues with accessing the SRAM in the D2 area properly. -JS
	//should test the different possible settings to see what works best while avoiding needing to manually clear the cache -JS

	MPU_Region_InitTypeDef MPU_InitStruct;

	  HAL_MPU_Disable();

	  MPU_InitStruct.Enable = MPU_REGION_ENABLE;

	  //D2 Domain�SRAM1
	  MPU_InitStruct.BaseAddress = 0x30000000;
	  // Increased region size to 256k. In Keshikan's code, this was 512 bytes (that's all that application needed).
	  // Each audio buffer takes up the frame size * 8 (16 bits makes it *2 and stereo makes it *2 and double buffering makes it *2)
	  // So a buffer size for read/write of 4096 would take up 64k = 4096*8 * 2 (read and write).
	  // I increased that to 256k so that there would be room for the ADC knob inputs and other peripherals that might require DMA access.
	  // we have a total of 256k in SRAM1 (128k, 0x30000000-0x30020000) and SRAM2 (128k, 0x30020000-0x3004000) of D2 domain.
	  // There is an SRAM3 in D2 domain as well (32k, 0x30040000-0x3004800) that is currently not mapped by the MPU (memory protection unit) controller.

	  MPU_InitStruct.Size = MPU_REGION_SIZE_256KB;

	  MPU_InitStruct.AccessPermission = MPU_REGION_FULL_ACCESS;

	  //AN4838
	  MPU_InitStruct.TypeExtField = MPU_TEX_LEVEL1;
	  MPU_InitStruct.IsCacheable = MPU_ACCESS_NOT_CACHEABLE;
	  MPU_InitStruct.IsBufferable = MPU_ACCESS_NOT_BUFFERABLE;
	  MPU_InitStruct.IsShareable = MPU_ACCESS_NOT_SHAREABLE;

	  //Shared Device
//	  MPU_InitStruct.TypeExtField = MPU_TEX_LEVEL0;
//	  MPU_InitStruct.IsCacheable = MPU_ACCESS_NOT_CACHEABLE;
//	  MPU_InitStruct.IsBufferable = MPU_ACCESS_BUFFERABLE;
//	  MPU_InitStruct.IsShareable = MPU_ACCESS_SHAREABLE;

	  MPU_InitStruct.Number = MPU_REGION_NUMBER0;

	  MPU_InitStruct.SubRegionDisable = 0x00;

	  MPU_InitStruct.DisableExec = MPU_INSTRUCTION_ACCESS_DISABLE;

	  HAL_MPU_ConfigRegion(&MPU_InitStruct);

	  //now set up D3 domain RAM

	  MPU_InitStruct.Enable = MPU_REGION_ENABLE;

	 	  //D2 Domain�SRAM1
	 	  MPU_InitStruct.BaseAddress = 0x38000000;

	 	  MPU_InitStruct.Size = MPU_REGION_SIZE_64KB;

	 	  MPU_InitStruct.AccessPermission = MPU_REGION_FULL_ACCESS;

	 	  //AN4838
	 	  MPU_InitStruct.TypeExtField = MPU_TEX_LEVEL1;
	 	  MPU_InitStruct.IsCacheable = MPU_ACCESS_CACHEABLE;
	 	  MPU_InitStruct.IsBufferable = MPU_ACCESS_BUFFERABLE;
	 	  MPU_InitStruct.IsShareable = MPU_ACCESS_SHAREABLE;

	 	  //Shared Device
	 //	  MPU_InitStruct.TypeExtField = MPU_TEX_LEVEL0;
	 //	  MPU_InitStruct.IsCacheable = MPU_ACCESS_NOT_CACHEABLE;
	 //	  MPU_InitStruct.IsBufferable = MPU_ACCESS_BUFFERABLE;
	 //	  MPU_InitStruct.IsShareable = MPU_ACCESS_SHAREABLE;

	 	  MPU_InitStruct.Number = MPU_REGION_NUMBER1;

	 	  MPU_InitStruct.SubRegionDisable = 0x00;

	 	  MPU_InitStruct.DisableExec = MPU_INSTRUCTION_ACCESS_ENABLE;

	 	  HAL_MPU_ConfigRegion(&MPU_InitStruct);

	  HAL_MPU_Enable(MPU_PRIVILEGED_DEFAULT);
}

/* USER CODE END 4 */

void Error_Handler(void)
{
  /* USER CODE BEGIN Error_Handler_Debug */
  /* User can add his own implementation to report the HAL error return state */
while(1)
{
;
}
  /* USER CODE END Error_Handler_Debug */
}
